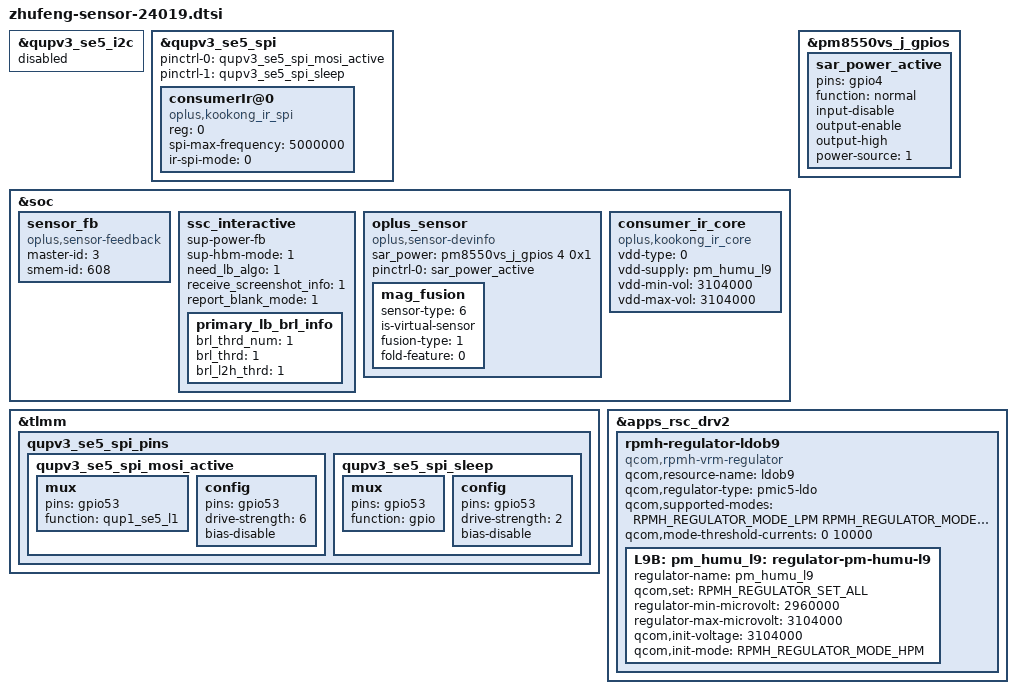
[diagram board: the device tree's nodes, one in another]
/**********************************************************************************
 * Copyright (c)  2022-2024  Guangdong oplus Mobile Comm Corp., Ltd
 * Description: oplus sensor dtsi
 *
 * Version: 1.0
 * Date: 2022-07-04
 *
 * ------------------------------ Revision History: --------------------------------
 * <version>         <date>        <author>                <desc>
 ***********************************************************************************/
#include <dt-bindings/regulator/qcom,rpmh-regulator-levels.h>

/* overlay default config and enable ir spi config */
&qupv3_se5_i2c {
    status = "disabled";
};

&qupv3_se5_spi{
    /delete-property/ pinctrl-0;
    /delete-property/ pinctrl-1;
    pinctrl-0 = <&qupv3_se5_spi_mosi_active>;
    pinctrl-1 = <&qupv3_se5_spi_sleep>;
};

&soc {
    //#ifdef OPLUS_FEATURE_SENSOR_SMEM
sensor_fb: sensor_fb {
               compatible = "oplus,sensor-feedback";
               master-id  = <3>;
               smem-id    = <608>;
           };
           ssc_interactive {
               sup-power-fb;
               sup-hbm-mode = <1>;
               need_lb_algo = <1>;
               receive_screenshot_info = <1>;
               report_blank_mode = <1>;

               primary_lb_brl_info {
                    brl_thrd_num = <1>;
                    brl_thrd = <1>;
                    brl_l2h_thrd = <1>;
               };
           };
           oplus_sensor {
               compatible = "oplus,sensor-devinfo";

               sar_power = <&pm8550vs_j_gpios 4 0x1>;
               pinctrl-names = "default";
               pinctrl-0 = <&sar_power_active>;

               /*virtual sensor*/
               mag_fusion {
                   sensor-type = <6>;//OPLUS_MAG_FUSION
                   is-virtual-sensor;
                   fusion-type = <1>;//AKM FUSION
                   fold-feature = <0>;
               };
           };
           consumer_ir_core {
               compatible = "oplus,kookong_ir_core";
               status = "okay";
               vdd-type = <0>; /*0: internal LDO , 1: external LOD*/
               vdd-supply = <&pm_humu_l9>;
               vdd-min-vol = <3104000>;
               vdd-max-vol = <3104000>;
           };
           //#endif /*OPLUS_FEATURE_SENSOR_SMEM*/
};

&pm8550vs_j_gpios {
	sar_power_active: sar_power_active {
		pins = "gpio4";
		function = "normal";
		input-disable;
		output-enable;
		output-high;
		power-source = <1>;
	};
};

&tlmm {
    qupv3_se5_spi_pins: qupv3_se5_spi_pins {
        qupv3_se5_spi_mosi_active: qupv3_se5_spi_mosi_active {
            mux {
                pins = "gpio53";
                function = "qup1_se5_l1";
            };

            config {
                pins = "gpio53";
                drive-strength = <6>;
                bias-disable;
            };
        };

        qupv3_se5_spi_sleep: qupv3_se5_spi_sleep {
            mux {
                pins = "gpio53";
                function = "gpio";
            };

            config {
                pins = "gpio53";
                drive-strength = <2>;
                bias-disable;
            };
        };
    };
};

//add for oplus consumerIr SPI mode
&qupv3_se5_spi{
    status = "ok";
    consumerIr@0 {
        compatible = "oplus,kookong_ir_spi";
        reg = <0>;
        status = "ok";

        spi-max-frequency = <5000000>;    /*4800000,9600000,15000000,19200000*/
        ir-spi-mode = <0>;
    };
};

&apps_rsc_drv2 {
    rpmh-regulator-ldob9 {
        compatible = "qcom,rpmh-vrm-regulator";
        qcom,resource-name = "ldob9";
        qcom,regulator-type = "pmic5-ldo";
        qcom,supported-modes =
            <RPMH_REGULATOR_MODE_LPM
            RPMH_REGULATOR_MODE_HPM>;
        qcom,mode-threshold-currents = <0 10000>;

        L9B: pm_humu_l9: regulator-pm-humu-l9 {
            regulator-name = "pm_humu_l9";
            qcom,set = <RPMH_REGULATOR_SET_ALL>;
            regulator-min-microvolt = <2960000>;
            regulator-max-microvolt = <3104000>;
            qcom,init-voltage = <3104000>;
            qcom,init-mode = <RPMH_REGULATOR_MODE_HPM>;
        };
    };
};


